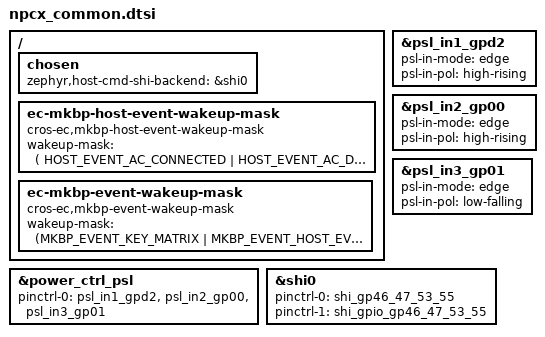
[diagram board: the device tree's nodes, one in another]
/* Copyright 2025 The ChromiumOS Authors
 * Use of this source code is governed by a BSD-style license that can be
 * found in the LICENSE file.
 */

#include <cros/integrated_fwid.dtsi>
#include <dt-bindings/wake_mask_event_defines.h>

/ {
	chosen {
		zephyr,host-cmd-shi-backend = &shi0;
	};

	ec-mkbp-host-event-wakeup-mask {
		compatible = "cros-ec,mkbp-host-event-wakeup-mask";
		wakeup-mask = <(
			HOST_EVENT_AC_CONNECTED |
			HOST_EVENT_AC_DISCONNECTED |
			HOST_EVENT_LID_OPEN |
			HOST_EVENT_POWER_BUTTON |
			HOST_EVENT_HANG_DETECT |
			HOST_EVENT_MODE_CHANGE)>;
	};

	ec-mkbp-event-wakeup-mask {
		compatible = "cros-ec,mkbp-event-wakeup-mask";
		wakeup-mask = <(MKBP_EVENT_KEY_MATRIX |
				MKBP_EVENT_HOST_EVENT)>;
	};
};

&psl_in1_gpd2 {
	/* Lid open */
	psl-in-mode = "edge";
	psl-in-pol = "high-rising";
};

&psl_in2_gp00 {
	/* AC present */
	psl-in-mode = "edge";
	psl-in-pol = "high-rising";
};

&psl_in3_gp01 {
	/* Power button */
	psl-in-mode = "edge";
	psl-in-pol = "low-falling";
};

/* Power domain device controlled by PSL (Power Switch Logic) IO pads */
&power_ctrl_psl {
	status = "okay";
	pinctrl-names = "sleep";
	pinctrl-0 = <&psl_in1_gpd2 &psl_in2_gp00 &psl_in3_gp01>;
};

/* host interface */
&shi0 {
	status = "okay";
	pinctrl-0 = <&shi_gp46_47_53_55>;
	pinctrl-1 = <&shi_gpio_gp46_47_53_55>;
	pinctrl-names = "default", "sleep";
};
